# nrf7140_application register map
Vendor: Nordic Semiconductor; Series: nRF71; File version: 1
CPU: CM33 r0p4, little endian, MPU, FPU, 3 interrupt priority bits, 480 interrupts, 8 SAU regions
Registers are 32-bit, read-write, reset 0x0 unless marked. A register's access mark holds for its fields unless they carry their own. Offsets are from the block's base; [hi:lo] are bit positions; lines under a group give offsets from that group; 'fields as' and 'values as' point back to an identical list.

## GLOBAL_VREGUSB_NS — VREGUSB peripheral 0
Base 0x5F967000
Same registers: GLOBAL_VREGUSB_S 0x5F967000 (alternate view of GLOBAL_VREGUSB_NS)
0x00 TASKS_START wo — Request power up of USB PM
  [0] TASKS_START
    1=Trigger task
0x04 TASKS_STOP wo — Stop requesting power up of USB PM
  [0] TASKS_STOP
    1=Trigger task
0x100 EVENTS_VBUSDETECTEDRAW — VBUS detected
  [0] EVENTS_VBUSDETECTEDRAW
    0=NotGenerated (Event not generated); 1=Generated (Event generated)
0x104 EVENTS_VBUSDETECTED — VBUS detected
  [0] EVENTS_VBUSDETECTED
    values as EVENTS_VBUSDETECTEDRAW.EVENTS_VBUSDETECTEDRAW
0x108 EVENTS_SETTLED0V8 — 0V8 settled
  [0] EVENTS_SETTLED0V8
    values as EVENTS_VBUSDETECTEDRAW.EVENTS_VBUSDETECTEDRAW
0x10C EVENTS_SETTLED3V3 — 3V3 settled
  [0] EVENTS_SETTLED3V3
    values as EVENTS_VBUSDETECTEDRAW.EVENTS_VBUSDETECTEDRAW
0x110 EVENTS_VBUSREMOVED — VBUS removed
  [0] EVENTS_VBUSREMOVED
    values as EVENTS_VBUSDETECTEDRAW.EVENTS_VBUSDETECTEDRAW
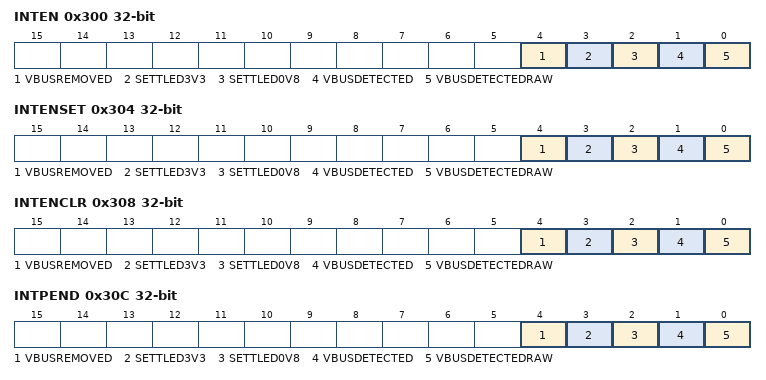
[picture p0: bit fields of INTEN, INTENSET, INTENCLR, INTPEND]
0x300 INTEN — Enable or disable interrupt
  [all] fields
    0=Disabled; 1=Enabled
  [4] VBUSREMOVED — Enable or disable interrupt for event VBUSREMOVED
  [3] SETTLED3V3 — Enable or disable interrupt for event SETTLED3V3
  [2] SETTLED0V8 — Enable or disable interrupt for event SETTLED0V8
  [1] VBUSDETECTED — Enable or disable interrupt for event VBUSDETECTED
  [0] VBUSDETECTEDRAW — Enable or disable interrupt for event VBUSDETECTEDRAW
0x304 INTENSET — Enable interrupt
  [all] fields
    on read: 0=Disabled (Read: Disabled); 1=Enabled (Read: Enabled) | on write: 1=Set (Enable)
  [4] VBUSREMOVED — Write '1' to enable interrupt for event VBUSREMOVED
  [3] SETTLED3V3 — Write '1' to enable interrupt for event SETTLED3V3
  [2] SETTLED0V8 — Write '1' to enable interrupt for event SETTLED0V8
  [1] VBUSDETECTED — Write '1' to enable interrupt for event VBUSDETECTED
  [0] VBUSDETECTEDRAW — Write '1' to enable interrupt for event VBUSDETECTEDRAW
0x308 INTENCLR — Disable interrupt
  [all] fields
    on read: 0=Disabled (Read: Disabled); 1=Enabled (Read: Enabled) | on write: 1=Clear (Disable)
  [4] VBUSREMOVED — Write '1' to disable interrupt for event VBUSREMOVED
  [3] SETTLED3V3 — Write '1' to disable interrupt for event SETTLED3V3
  [2] SETTLED0V8 — Write '1' to disable interrupt for event SETTLED0V8
  [1] VBUSDETECTED — Write '1' to disable interrupt for event VBUSDETECTED
  [0] VBUSDETECTEDRAW — Write '1' to disable interrupt for event VBUSDETECTEDRAW
0x30C INTPEND ro — Pending interrupts
  [all] fields
    on read: 0=NotPending (Read: Not pending); 1=Pending (Read: Pending)
  [4] VBUSREMOVED — Read pending status of interrupt for event VBUSREMOVED
  [3] SETTLED3V3 — Read pending status of interrupt for event SETTLED3V3
  [2] SETTLED0V8 — Read pending status of interrupt for event SETTLED0V8
  [1] VBUSDETECTED — Read pending status of interrupt for event VBUSDETECTED
  [0] VBUSDETECTEDRAW — Read pending status of interrupt for event VBUSDETECTEDRAW
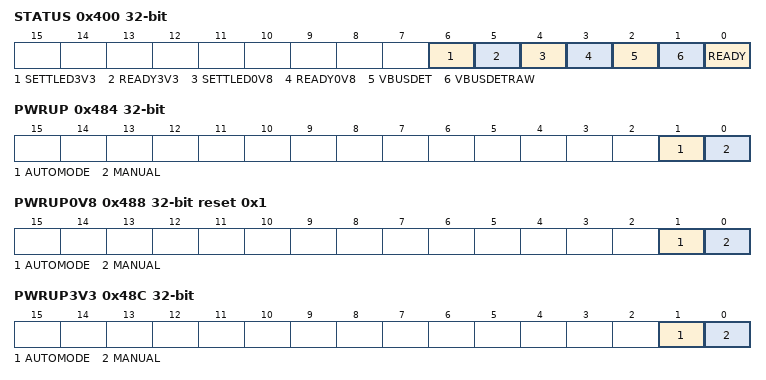
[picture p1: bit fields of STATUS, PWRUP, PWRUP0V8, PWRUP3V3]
0x400 STATUS ro — Status of USB PM
  [6] SETTLED3V3 — Power 3V3 settled
    0=NotSettled3v3 (Power 3V3 not settled); 1=Settled3v3 (Power 3V3 settled)
  [5] READY3V3 — Power 3V3 ready
    0=NotReady3v3 (Power 3V3 not ready); 1=Ready3v3 (Power 3V3 ready)
  [4] SETTLED0V8 — Power 0V8 settled
    0=NotSettled0v8 (Power 0V8 not settled); 1=Settled0v8 (Power 0V8 settled)
  [3] READY0V8 — Power 0V8 ready
    0=NotReady0v8 (Power 0V8 not ready); 1=Ready0v8 (Power 0V8 ready)
  [2] VBUSDET — VBUS detected, filtered
    0=NotVbusDet (VBUS not detected); 1=VBUS detected
  [1] VBUSDETRAW — VBUS detected, raw signal
    0=NotVbusDetRaw (VBUS not detected); 1=VbusDetRaw (VBUS detected)
  [0] READY — USB PM ready
    0=PowerDown (USB PM powered down); 1=Powered (USB PM powered up)
0x410 CONFIG group — Unspecified
  0x00 RDYTIM reset 0x18 — Time from pwrupPm to ready signal (0us-3us)
    [5:0] VAL — Timer value
      0=Min (0 us); 24=Default (1.5 us); 48=Max (3 us)
  0x04 VBRFT reset 0xA0 — Time from VBUSDETRAW until filtered VBUSDET (0us-500us)
    [12:0] VAL — Timer value
      0=Min (0 us); 160=Default (10 us); 0x1F40=Max (500 us)
  0x08 RDYLDOSTIM reset 0x10 — Time from powerup LDOs until ready (0us-10us)
    [7:0] VAL — Timer value
      0=Min (0 us); 10=Default (1 us); 160=Max (10 us)
  0x0C SETL0V8TIM reset 0xFA0 — Time from LDOs ready to SETTLED0V8 (125us-1000us)
    [13:0] VAL — Timer value
      0x7D0=Min (125 us); 0xFA0=Default (250 us); 0x3E80=Max (1000 us)
  0x10 SETL3V3TIM reset 0xFA0 — Time from SETTLED0V8 to SETTLED3V3 (0us-1000us)
    [13:0] VAL — Timer value
      0=Min (0 us); 0xFA0=Default (250 us); 0x3E80=Max (1000 us)
  0x14 WUEXT reset 0x4 — Prolong of the wakeup pulse. 2+VAL clock cycles min length of the pulse.
    [2:0] VAL — Wakeup prolong
0x440 TRIM group — Unspecified
  0x00 TRIMVDD reset 0x8 — Trim USB PM internal 1.8V voltage
    [3:0] VAL — Voltage offset trimming value
  0x04 TRIMIBP reset 0x8 — Trim 10uA IBP bias current
    [3:0] VAL — Bias current trimming value
  0x08 TRIM0V8 reset 0x8 — Trim USB PHY 0.8V DVDD
    [3:0] VAL — Voltage offset trimming value
  0x0C TRIM3V3 reset 0x8 — Trim USB PHY 3.3V VDD
    [3:0] VAL — Voltage offset trimming value
0x480 MIRROR reset 0x1 — Enable LOCK for mirrored registers
  [0] LOCK — Lock for mirrored registers
    0=Disabled (Lock disabled); 1=Enabled (Lock enabled)
0x484 PWRUP — Power up USB PM
  [1] AUTOMODE — Automatic power mode configuration
    0=Auto (USB PM automatically powered); 1=Manual (USB PM manually powered)
  [0] MANUAL — Manual power mode configuration
    0=Off (USB PM powered down in manual mode); 1=On (USB PM powered up in manual mode)
0x488 PWRUP0V8 reset 0x1 — Power up 0V8
  [1] AUTOMODE — Automatic power mode configuration
    0=Auto (USB 0V8 regulator automatically powered); 1=Manual (USB 0V8 regulator manually powered)
  [0] MANUAL — Manual power mode configuration for 0V8 regulator
    0=Off (USB 0V8 regulator powered down in manual mode); 1=On (USB 0V8 regulator powered up in manual mode)
0x48C PWRUP3V3 — Power up 3V3
  [1] AUTOMODE — Automatic power mode configuration
    0=Auto (USB 3V3 regulator automatically powered); 1=Manual (USB 3V3 regulator manually powered)
  [0] MANUAL — Manual power mode configuration for 0V8 regulator
    0=Off (USB 3V3 regulator powered down in manual mode); 1=On (USB 3V3 regulator powered up in manual mode)
0x500 OVERRIDE group — Unspecified
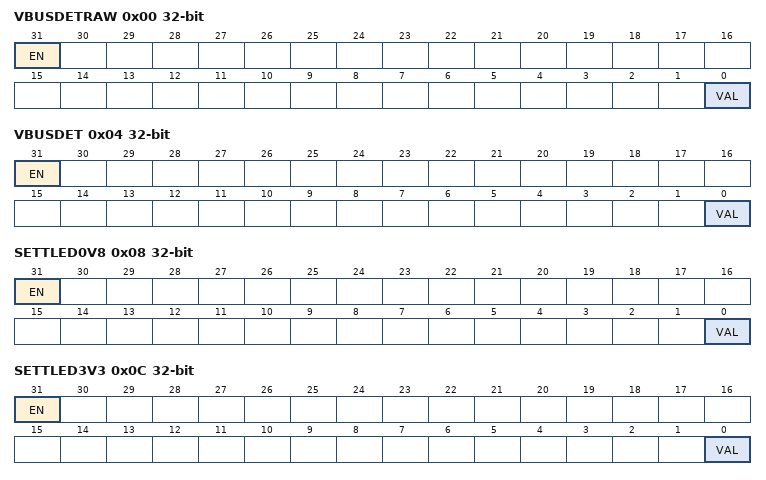
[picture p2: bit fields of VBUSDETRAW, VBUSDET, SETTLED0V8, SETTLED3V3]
  0x00 VBUSDETRAW — Override the raw VBUSDET from the analog module
    [31] EN — Enable the override
      0=Disabled (Override is disabled); 1=Enabled (Override is enabled)
    [0] VAL — Override value for the signal
  0x04 VBUSDET — Override the filtered VBUSDET from the digital part
    fields as OVERRIDE.VBUSDETRAW
  0x08 SETTLED0V8 — Override the SETTLED0V8 from the digital part
    fields as OVERRIDE.VBUSDETRAW
  0x0C SETTLED3V3 — Override the SETTLED3V3 from the digital part
    fields as OVERRIDE.VBUSDETRAW
0x600 DFT group — Unspecified
  0x00 ATB0CONFIG — Analog Test Bus 0 (ATB0) configuration
    [31] EN — Enable the analog test bus
      0=Disabled (Analog test bus is disabled); 1=Enabled (Analog test bus is enabled)
  0x04 ATB1CONFIG — Analog Test Bus 1 (ATB1) configuration
    fields as DFT.ATB0CONFIG
  0x10 DTB0CONFIG — Digital Test Bus 0 (DTB0) configuration
    [31] EN — Enable the digital test bus
      0=Disabled (Digital test bus is disabled); 1=Enabled (Digital test bus is enabled)
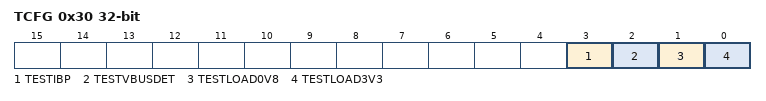
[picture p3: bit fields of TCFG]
  0x30 TCFG — Test mode configuration
    [all] fields
      0=Disabled (Normal operation); 1=Enabled (Test mode enabled)
    [3] TESTIBP — IBP test
    [2] TESTVBUSDET — VBUS det test
    [1] TESTLOAD0V8 — Test load LDO 0V8
    [0] TESTLOAD3V3 — Test load LDO 3V3
